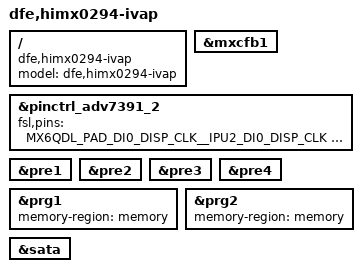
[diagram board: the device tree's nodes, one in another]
/*
 * Copyright 2015 DResearch Fahrzeugelektronik GmbH
 * Copyright 2013 Boundary Devices
 * Copyright 2012 Freescale Semiconductor, Inc.
 * Copyright 2011 Linaro Ltd.
 *
 * The code contained herein is licensed under the GNU General Public
 * License. You may obtain a copy of the GNU General Public License
 * Version 2 or later at the following locations:
 *
 * http://www.opensource.org/licenses/gpl-license.html
 * http://www.gnu.org/copyleft/gpl.html
 */

/dts-v1/;
#include <dt-bindings/interrupt-controller/irq.h>
#include "imx6q.dtsi"
#include "imx6qp.dtsi"
#include "imx6qdl-himx0294-dvrec.dtsi"

/ {
	model = "dfe,himx0294-ivap";
	compatible = "dfe,himx0294-ivap", "fsl,imx6qp";
};

&mxcfb1 {
	status = "okay";
};

&pinctrl_adv7391_2 {
	fsl,pins = <
		MX6QDL_PAD_DI0_DISP_CLK__IPU2_DI0_DISP_CLK 0x10		/* Pixclk */
		MX6QDL_PAD_DISP0_DAT12__IPU2_DISP0_DATA12  0x10
		MX6QDL_PAD_DISP0_DAT13__IPU2_DISP0_DATA13  0x10
		MX6QDL_PAD_DISP0_DAT14__IPU2_DISP0_DATA14  0x10
		MX6QDL_PAD_DISP0_DAT15__IPU2_DISP0_DATA15  0x10
		MX6QDL_PAD_DISP0_DAT16__IPU2_DISP0_DATA16  0x10
		MX6QDL_PAD_DISP0_DAT17__IPU2_DISP0_DATA17  0x10
		MX6QDL_PAD_DISP0_DAT18__IPU2_DISP0_DATA18  0x10
		MX6QDL_PAD_DISP0_DAT19__IPU2_DISP0_DATA19  0x10
	>;
};

&pre1 {
	status = "okay";
};

&pre2 {
	status = "okay";
};

&pre3 {
	status = "okay";
};

&pre4 {
	status = "okay";
};

&prg1 {
	memory-region = <&memory>;
	status = "okay";
};

&prg2 {
	memory-region = <&memory>;
	status = "okay";
};

&sata {
	status = "okay";
};

